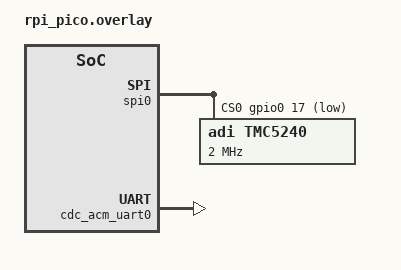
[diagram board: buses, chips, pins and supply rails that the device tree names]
/*
 * SPDX-FileCopyrightText: Copyright (c) 2024 Nathan Perry <np@npry.dev>
 * SPDX-License-Identifier: MIT OR Apache-2.0
 */

&spi0 {
	status = "okay";

	cs-gpios = <&gpio0 17 GPIO_ACTIVE_LOW>;

	tmc5240@0 {
		compatible = "adi,tmc5240";
		status = "okay";
		reg = <0>;
		spi-max-frequency = <2000000>;
	};
};

/ {
	chosen {
		zephyr,console = &cdc_acm_uart0;
	};
};

&zephyr_udc0 {
	cdc_acm_uart0: cdc_acm_uart0 {
		compatible = "zephyr,cdc-acm-uart";
	};
};
